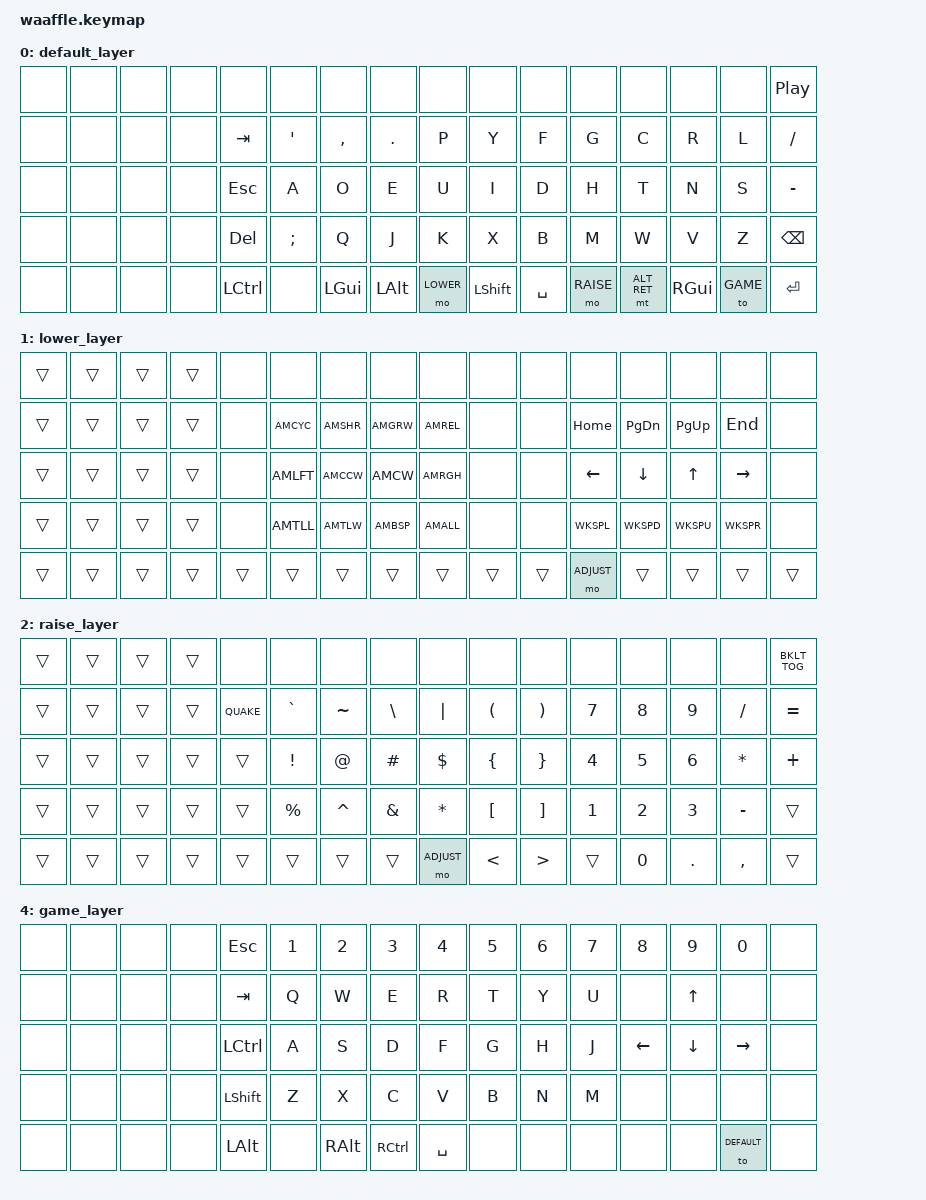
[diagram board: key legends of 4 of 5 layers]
/*
 * Copyright (c) 2020 dELLIKEEb
 *
 * SPDX-License-Identifier: MIT
 */

#include <behaviors.dtsi>
#include <dt-bindings/zmk/keys.h>
#include <dt-bindings/zmk/bt.h>
#include <dt-bindings/zmk/rgb.h>

// custom keycode defs for easier access
#define DEFAULT 0
#define LOWER   1
#define RAISE   2
#define ADJUST  3
#define GAME    4

#define AMCYC  LA(LS(SPACE))
#define AMSHR  LA(LS(DOT))
#define AMGRW  LA(LS(COMMA))
#define AMREL  LA(LS(Z))
#define AMLFT  LA(LS(H))
#define AMCCW  LA(LS(J))
#define AMCW   LA(LS(K))
#define AMRGH  LA(LS(L))
#define AMTLL  LA(LS(N1))
#define AMTLW  LA(LS(N2))
#define AMBSP  LA(LS(N3))
#define AMALL  LA(LS(N4))

#define WKSPL  LA(LC(LEFT))
#define WKSPD  LA(LC(DOWN))
#define WKSPU  LA(LC(UP))
#define WKSPR  LA(LC(RIGHT))

#define QUAKE LG(GRAV)

#define ALT_RET RALT RET

#define RSTCLR RGB_COLOR_HSB(0,100,100)

#define BT0  BT_SEL 0
#define BT1  BT_SEL 1
#define BT2  BT_SEL 2
#define BT3  BT_SEL 3
#define BT4  BT_SEL 4

/ {
    keymap {
        compatible = "zmk,keymap";

        default_layer {
            bindings = <
                &none       &none       &none       &none       &none      &none       &none       &none       &none     &none       &none       &none       &none       &none       &none       &kp C_PP
                &none       &none       &none       &none       &kp TAB    &kp SQT     &kp COMMA   &kp DOT     &kp P     &kp Y       &kp F       &kp G       &kp C       &kp R       &kp L       &kp FSLH
                &none       &none       &none       &none       &kp ESC    &kp A       &kp O       &kp E       &kp U     &kp I       &kp D       &kp H       &kp T       &kp N       &kp S       &kp MINUS
                &none       &none       &none       &none       &kp DEL    &kp SEMI    &kp Q       &kp J       &kp K     &kp X       &kp B       &kp M       &kp W       &kp V       &kp Z       &kp BSPC
                &none       &none       &none       &none       &kp LCTL   &none       &kp LGUI    &kp LALT    &mo LOWER &kp LSHFT   &kp SPACE   &mo RAISE   &mt ALT_RET &kp RGUI    &to GAME    &kp RET
            >;
            sensor-bindings = <&inc_dec_kp C_VOL_DN C_VOL_UP>;
        };

        lower_layer {
            bindings = <
                &trans      &trans      &trans      &trans      &none       &none       &none       &none       &none       &none       &none       &none       &none       &none       &none       &none
                &trans      &trans      &trans      &trans      &none       &kp AMCYC   &kp AMSHR   &kp AMGRW   &kp AMREL   &none       &none       &kp HOME    &kp PG_DN   &kp PG_UP   &kp END     &none
                &trans      &trans      &trans      &trans      &none       &kp AMLFT   &kp AMCCW   &kp AMCW    &kp AMRGH   &none       &none       &kp LEFT    &kp DOWN    &kp UP      &kp RIGHT   &none
                &trans      &trans      &trans      &trans      &none       &kp AMTLL   &kp AMTLW   &kp AMBSP   &kp AMALL   &none       &none       &kp WKSPL   &kp WKSPD   &kp WKSPU   &kp WKSPR   &none
                &trans      &trans      &trans      &trans      &trans      &trans      &trans      &trans      &trans      &trans      &trans      &mo ADJUST  &trans      &trans      &trans      &trans
            >;
            sensor-bindings = <&inc_dec_kp C_AC_SCROLL_DOWN C_AC_SCROLL_UP>;
        };

        raise_layer {
            bindings = <
                &trans      &trans      &trans      &trans      &none       &none       &none       &none       &none       &none       &none       &none       &none       &none       &none       &kp C_BKLT_TOG
                &trans      &trans      &trans      &trans      &kp QUAKE   &kp GRAV    &kp TILDE   &kp BSLH    &kp PIPE    &kp LPAR    &kp RPAR    &kp N7      &kp N8      &kp N9      &kp FSLH    &kp EQUAL
                &trans      &trans      &trans      &trans      &trans      &kp EXCL    &kp AT      &kp HASH    &kp DLLR    &kp LBRC    &kp RBRC    &kp N4      &kp N5      &kp N6      &kp ASTRK   &kp PLUS
                &trans      &trans      &trans      &trans      &trans      &kp PRCNT   &kp CARET   &kp AMPS    &kp ASTRK   &kp LBKT    &kp RBKT    &kp N1      &kp N2      &kp N3      &kp MINUS   &trans
                &trans      &trans      &trans      &trans      &trans      &trans      &trans      &trans      &mo ADJUST  &kp LT      &kp GT      &trans      &kp N0      &kp DOT     &kp COMMA   &trans
            >;
            sensor-bindings = <&inc_dec_kp C_BRI_DN C_BRI_UP>;
        };

        adjust_layer {
            bindings = <
                &trans      &trans      &trans      &trans      &bootloader &bt BT_SEL 0     &bt BT_SEL 1    &bt BT_SEL 2     &bt BT_SEL 3      &bt BT_SEL 4    &none       &none       &none       &none       &bt BT_CLR  &none
                &trans      &trans      &trans      &trans      &sys_reset  &none            &none           &none            &none             &none           &none       &kp F9      &kp F10     &kp F11     &kp F12     &none
                &trans      &trans      &trans      &trans      &none       &none            &none           &none            &none             &none           &none       &kp F5      &kp F6      &kp F7      &kp F8      &none
                &trans      &trans      &trans      &trans      &none       &none            &none           &none            &none             &none           &none       &kp F1      &kp F2      &kp F3      &kp F4
                &trans      &trans      &trans      &trans      &none       &trans           &trans          &trans           &trans            &trans          &trans      &trans      &trans      &trans      &trans      &trans
            >;
        };

        game_layer {
            bindings = <
                &none       &none       &none       &none       &kp ESC     &kp N1      &kp N2      &kp N3      &kp N4    &kp N5      &kp N6      &kp N7      &kp N8      &kp 9       &kp 0       &none
                &none       &none       &none       &none       &kp TAB     &kp Q       &kp W       &kp E       &kp R     &kp T       &kp Y       &kp U       &none       &kp UP      &none       &none
                &none       &none       &none       &none       &kp LCTL    &kp A       &kp S       &kp D       &kp F     &kp G       &kp H       &kp J       &kp LEFT    &kp DOWN    &kp RIGHT   &none
                &none       &none       &none       &none       &kp LSHFT   &kp Z       &kp X       &kp C       &kp V     &kp B       &kp N       &kp M       &none       &none       &none       &none
                &none       &none       &none       &none       &kp LALT    &none       &kp RALT    &kp RCTL    &kp SPACE &none       &none       &none       &none       &none       &to DEFAULT &none
            >;
            sensor-bindings = <&inc_dec_kp C_VOL_DN C_VOL_UP>;
        };

    };
};
